AUTOSAR XML (schema 4-2-2)
package /Components
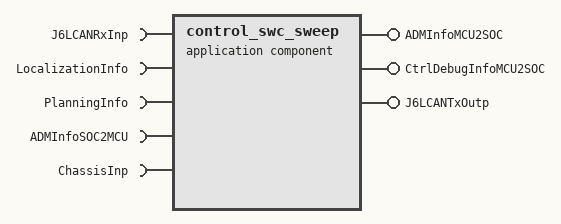
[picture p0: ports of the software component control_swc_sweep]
  application sw component type control_swc_sweep
    5 x require port:
      J6LCANRxInp: nonqueued-receiver-com-spec{data-element=J6LCANRxInp, init-value={short-label=DefaultInitValue_J6L_RxBus, fields=[0, 0, 0, 0, 0, 0, 0, 0, 0, 0, 0, 0, 0, 0, 0, 0, 0, 0, 0, 0, 0, 0, 0, 0, 0, 0, 0, 0, 0, 0, 0, 0, 0, 0, 0, 0, 0, 0, 0, 0, 0, 0, 0, 0, 0, 0, 0, 0, 0, 0, 0, 0, 0, 0, 0, 0, 0, 0, 0, 0, 0, 0, 0, 0, 0, 0, 0, 0, 0, 0, 0, 0, 0, 0, 0, 0, 0, 0, 0, 0, 0, 0, 0, 0, 0, 0, 0, 0, 0, 0, 0, 0, 0, 0, 0, 0, 0, 0, 0, 0, 0, 0, 0, 0, 0, 0, 0, 0, 0, 0, 0, 0, 0, 0, 0, 0, 0, 0, 0, 0, 0, 0, 0, 0, 0, 0, 0, 0, 0, 0, 0, 0, 0, 0, 0, 0, 0, 0, 0, 0, 0, 0, 0, 0, 0, 0, 0, 0, 0, 0, 0, 0, 0, 0, 0, 0, 0, 0, 0, 0, 0, 0, 0, 0, 0, 0, 0, 0, 0, 0, 0, 0, 0, 0, 0, 0, 0, 0, 0, 0, 0, 0, 0, 0, 0, 0, 0, 0, 0, 0, 0, 0, 0, 0, 0, 0, 0, 0, 0, 0, 0, 0, 0, 0, 0, 0, 0, 0, 0, 0, 0, 0, 0, 0, 0, 0, 0, 0, 0, 0, 0, 0, 0, 0, 0, 0, 0, 0, 0, 0, 0, 0, 0, 0, 0, 0, 0, 0, 0, 0, 0, 0, 0, 0, 0, 0, 0, 0, 0, 0, 0, 0, 0, 0, 0, 0, 0, 0, 0, 0, 0, 0, 0, 0, 0, 0, 0, 0, 0, 0, 0, 0, 0, 0, 0, 0, 0, 0, 0, 0, 0, 0, 0, 0, 0, 0, 0, 0, 0, 0, 0, 0, 0, 0, 0, 0, 0, 0, 0, 0, 0, 0, 0, 0, 0, 0, 0, 0, 0, 0, 0, 0, 0, 0, 0, 0, 0, 0, 0, 0, 0, 0, 0, 0, 0, 0, 0, 0, 0, 0, 0, 0, 0, 0, 0, 0, 0, 0, 0, 0, 0, 0, 0, 0, 0, 0, 0, 0, 0, 0, 0, 0, 0, 0, 0, 0, 0, 0, 0, 0, 0]}}, required-interface=J6LCANRxInp
      LocalizationInfo: nonqueued-receiver-com-spec{data-element=LocalizationInfo, init-value={short-label=DefaultInitValue_LocalizationInfo, fields=[0, 0, 0, 0, 0, 0, 0, [0, 0, 0], [0, 0, 0, 0], [0, 0, 0], [0, 0, 0], [0, 0, 0], 0, [0, 0, 0], [0, 0, 0], [0, 0, 0], [0, 0, 0], 0, 0, [0, 0, 0], [0, 0, 0], [0, 0, 0], 0, 0, 0]}}, required-interface=LocalizationInfo
      PlanningInfo: nonqueued-receiver-com-spec{data-element=PlanningInfo, init-value={short-label=DefaultInitValue_PlanningInfo, fields=[0, 0, 0, 0, 0, 0, 0, 0, 0, 0, {short-label=DefaultInitValue_TrajectoryPoint, fields=[100 x 0, 100 x 0, 100 x 0, 100 x 0, 100 x 0, 100 x 0, 100 x 0, 100 x 0, 100 x 0, 100 x 0, 100 x 0, 100 x 0, 100 x 0]}, 0, {short-label=DefaultInitValue_PathPoint, fields=[100 x 0, 100 x 0, 100 x 0, 100 x 0, 100 x 0, 100 x 0, 100 x 0]}, 0, 0, 0, 0, 0, 0, 0, 0, 0, 0, 0, 0, 0, 0, {short-label=DefaultInitValue_VehicleSignal, fields=[0, 0, 0, 0, 0]}, 0, 0]}}, required-interface=PlanningInfo
      ADMInfoSOC2MCU: nonqueued-receiver-com-spec{data-element=ADMInfoSOC2MCU, init-value={short-label=DefaultInitValue_ADMInfoSOC2MCU, fields=[0, 0, 0, 0, 0, 0, 0, 0, 0, 0, 0, 0, 0, 0, 0, 0, 0, 0, 0, 0, 0, 0, 0, 0, 0, 0, 0]}}, required-interface=ADMInfoSOC2MCU
      ChassisInp: nonqueued-receiver-com-spec{data-element=ChassisInp, init-value={short-label=DefaultInitValue_ChassisInfo, fields=[0, 0, 0, 0, 0, 0, 0, 0, 0, 0, 0, 0, 0, 0, 0, 0, 0, 0, 0, 0, 0, 0, 0, 0, 0, 0, 0, 0, 0, 0, 0, 0, 0, 0, 0, 0, 0, 0, 0, 0, 0, 0, 0, 0, 0, 0, 0, 0, 0, 0, 0, 0, 0, 0, 0, 0, 0, 0, 0, 0, 0, 0, 0, 0, 0, 0, 0, 0, 0, 0, 0, 0, 0, 0, 0, 0, 0, 0, 0, 0, 0, 0, 0, 0, 0, 0, 0, 0, 0, 0, 0, 0, 0, 0, 0, 0, 0, 0, 0, 0, 0, 0, 0, 0, 0, 0, 0, 0, 0, 0, 0, 0, 0, 0, 0, 0, 0, 0, 0, 0, 0, 0, 0, 0, 0, 0, 0, 0, 0, 0, 0]}}, required-interface=ChassisInp
    provide port ADMInfoMCU2SOC: nonqueued-sender-com-spec{data-element=ADMInfoMCU2SOC, init-value={short-label=DefaultInitValue_ADMInfoMCU2SOC, fields=[0, 0, 0, 0, 0, 0, 0, 0]}}, provided-interface=ADMInfoMCU2SOC
    provide port CtrlDebugInfoMCU2SOC: nonqueued-sender-com-spec{data-element=CtrlDebugInfoMCU2SOC, init-value={short-label=DefaultInitValue_CtrlInfoMCU2SOC, fields=[0, 0, 0, 0, 0, 0, 0, 0, 0, 0, 0, 0, 0, 0, 0, 0, 0, 0, 0, 0, 0, 0, 0, 0, 0, 0, 0, 0, 0, 0, 0, 0, 0, 0, 0, 0, 0, 0, 0, 0, 0, 0, 0, 0, 0, 0, 0, 0, 0, 0, 0, 0, 0, 0, 0, 0, 0, 0, 0, 0, 0, 0, 0, 0, 0, 0, 0]}}, provided-interface=CtrlDebugInfoMCU2SOC
    provide port J6LCANTxOutp: nonqueued-sender-com-spec{data-element=J6LCANTxOutp, init-value={short-label=DefaultInitValue_J6L_TxBus, fields=[0, 0, 0, 0, 0, 0, 0, 0, 0, 0, 0, 0, 0, 0, 0, 0, 0, 0, 0, 0, 0, 0, 0, 0, 0, 0, 0, 0, 0, 0, 0, 0, 0, 0, 0, 0, 0, 0, 0, 0, 0, 0, 0, 0, 0, 0, 0, 0, 0, 0, 0, 0, 0, 0, 0, 0, 0, 0, 0, 0, 0, 0, 0, 0, 0, 0, 0, 0, 0, 0, 0, 0, 0, 0, 0, 0, 0, 0, 0, 0, 0, 0]}}, provided-interface=J6LCANTxOutp
    behavior control_swc_sweep_IB: handle-termination-and-restart=NO-SUPPORT
      constant-memorys:
        122 x parameter data prototype, all with sw-calibration-access=READ-WRITE:
          k_CRM_LatCrvtPrvTi: category=VALUE, type=Double_const, init-value=constant-reference={short-label=k_CRM_LatCrvtPrvTi, constant=k_CRM_LatCrvtPrvTi}
          k_CRM_LatErrPrvTi: category=VALUE, type=Double_const, init-value=constant-reference={short-label=k_CRM_LatErrPrvTi, constant=k_CRM_LatErrPrvTi}
          k_CRM_LongPrvTi: category=VALUE, type=Double_const, init-value=constant-reference={short-label=k_CRM_LongPrvTi, constant=k_CRM_LongPrvTi}
          k_Lat_SteerAnglErrDisThres: category=VALUE, type=Double_const, init-value=constant-reference={short-label=k_Lat_SteerAnglErrDisThres, constant=k_Lat_SteerAnglErrDisThres}
          k_Lat_SteerAnglOffsetIni: category=VALUE, type=Double_const, init-value=constant-reference={short-label=k_Lat_SteerAnglOffsetIni, constant=k_Lat_SteerAnglOffsetIni}
          k_Lat_SteerAngloffsetAnglThres: category=VALUE, type=Double_const, init-value=constant-reference={short-label=k_Lat_SteerAngloffsetAnglThres, constant=k_Lat_SteerAngloffsetAnglThres}
          k_Lat_SteerAngloffsetHidingErrThres: category=VALUE, type=Double_const, init-value=constant-reference={short-label=k_Lat_SteerAngloffsetHidingErrThres, constant=k_Lat_SteerAngloffsetHidingErrThres}
          k_Lat_SteerAngloffsetHoldTi: category=VALUE, type=Double_const, init-value=constant-reference={short-label=k_Lat_SteerAngloffsetHoldTi, constant=k_Lat_SteerAngloffsetHoldTi}
          k_Lat_SteerAngloffsetLatErrThres: category=VALUE, type=Double_const, init-value=constant-reference={short-label=k_Lat_SteerAngloffsetLatErrThres, constant=k_Lat_SteerAngloffsetLatErrThres}
          k_Lat_SteerAngloffsetWaitTi: category=VALUE, type=Double_const, init-value=constant-reference={short-label=k_Lat_SteerAngloffsetWaitTi, constant=k_Lat_SteerAngloffsetWaitTi}
          k_SigMap_brake_accel_deadzone: category=VALUE, type=Double_const, init-value=constant-reference={short-label=k_SigMap_brake_accel_deadzone, constant=k_SigMap_brake_accel_deadzone}
          k_CRM_DstErrCalibration: category=VALUE, type=Float_const, init-value=constant-reference={short-label=k_CRM_DstErrCalibration, constant=k_CRM_DstErrCalibration}
          k_CRM_LongRefAccCalibration: category=VALUE, type=Float_const, init-value=constant-reference={short-label=k_CRM_LongRefAccCalibration, constant=k_CRM_LongRefAccCalibration}
          k_CRM_LongRefSpdCalibration: category=VALUE, type=Float_const, init-value=constant-reference={short-label=k_CRM_LongRefSpdCalibration, constant=k_CRM_LongRefSpdCalibration}
          k_EPS_StrAnglGain: category=VALUE, type=Float_const, init-value=constant-reference={short-label=k_EPS_StrAnglGain, constant=k_EPS_StrAnglGain}
          k_Lat_DefaultCmd: category=VALUE, type=Float_const, init-value=constant-reference={short-label=k_Lat_DefaultCmd, constant=k_Lat_DefaultCmd}
          k_Lat_DeltaFeedbackStrWhlAngUp: category=ARRAY, type=rt_Array_Float_22_const, init-value=constant-reference={short-label=k_Lat_DeltaFeedbackStrWhlAngUp, constant=k_Lat_DeltaFeedbackStrWhlAngUp}
          k_Lat_DeltaFeedbackStrWhlAngUpUturn: category=VALUE, type=Float_const, init-value=constant-reference={short-label=k_Lat_DeltaFeedbackStrWhlAngUpUturn, constant=k_Lat_DeltaFeedbackStrWhlAngUpUturn}
          k_Lat_DeltaFeedforwardStrWhlAngUp: category=ARRAY, type=rt_Array_Float_22_const, init-value=constant-reference={short-label=k_Lat_DeltaFeedforwardStrWhlAngUp, constant=k_Lat_DeltaFeedforwardStrWhlAngUp}
          k_Lat_DeltaFeedforwardStrWhlAngUpUturn: category=VALUE, type=Float_const, init-value=constant-reference={short-label=k_Lat_DeltaFeedforwardStrWhlAngUpUturn, constant=k_Lat_DeltaFeedforwardStrWhlAngUpUturn}
          k_Lat_DeltaStrWhlAngUp: category=ARRAY, type=rt_Array_Float_22_const, init-value=constant-reference={short-label=k_Lat_DeltaStrWhlAngUp, constant=k_Lat_DeltaStrWhlAngUp}
          k_Lat_DeltaStrWhlAngUpUturn: category=VALUE, type=Float_const, init-value=constant-reference={short-label=k_Lat_DeltaStrWhlAngUpUturn, constant=k_Lat_DeltaStrWhlAngUpUturn}
          k_Lat_DeltaStrWhlAnglforBias: category=VALUE, type=Float_const, init-value=constant-reference={short-label=k_Lat_DeltaStrWhlAnglforBias, constant=k_Lat_DeltaStrWhlAnglforBias}
          k_Lat_DuWeight: category=VALUE, type=Float_const, init-value=constant-reference={short-label=k_Lat_DuWeight, constant=k_Lat_DuWeight}
          k_Lat_FbResetVxThd: category=VALUE, type=Float_const, init-value=constant-reference={short-label=k_Lat_FbResetVxThd, constant=k_Lat_FbResetVxThd}
          k_Lat_LQR_HeadingError_Weights: category=ARRAY, type=rt_Array_Float_22_const, init-value=constant-reference={short-label=k_Lat_LQR_HeadingError_Weights, constant=k_Lat_LQR_HeadingError_Weights}
          k_Lat_LQR_K_Matrics: category=ARRAY, type=rt_Array_Float_292_const, init-value=constant-reference={short-label=k_Lat_LQR_K_Matrics, constant=k_Lat_LQR_K_Matrics}
          k_Lat_LQR_LatError_Weights: category=ARRAY, type=rt_Array_Float_22_const, init-value=constant-reference={short-label=k_Lat_LQR_LatError_Weights, constant=k_Lat_LQR_LatError_Weights}
          k_Lat_ManualCmd: category=VALUE, type=Float_const, init-value=constant-reference={short-label=k_Lat_ManualCmd, constant=k_Lat_ManualCmd}
          k_Lat_MaxLatAcc: category=VALUE, type=Float_const, init-value=constant-reference={short-label=k_Lat_MaxLatAcc, constant=k_Lat_MaxLatAcc}
          k_Lat_MaxStrWhlAng: category=ARRAY, type=rt_Array_Float_22_const, init-value=constant-reference={short-label=k_Lat_MaxStrWhlAng, constant=k_Lat_MaxStrWhlAng}
          k_Lat_PPMinDist: category=VALUE, type=Float_const, init-value=constant-reference={short-label=k_Lat_PPMinDist, constant=k_Lat_PPMinDist}
          k_Lat_PP_PrvTi: category=VALUE, type=Float_const, init-value=constant-reference={short-label=k_Lat_PP_PrvTi, constant=k_Lat_PP_PrvTi}
          k_Lat_SteerAngloffset: category=VALUE, type=Float_const, init-value=constant-reference={short-label=k_Lat_SteerAngloffset, constant=k_Lat_SteerAngloffset}
          k_Lat_UWeight: category=VALUE, type=Float_const, init-value=constant-reference={short-label=k_Lat_UWeight, constant=k_Lat_UWeight}
          k_Lat_feedforwardhidingindex: category=ARRAY, type=rt_Array_Float_25_const, init-value=constant-reference={short-label=k_Lat_feedforwardhidingindex, constant=k_Lat_feedforwardhidingindex}
          k_Lat_feedforwardindex: category=ARRAY, type=rt_Array_Float_25_const, init-value=constant-reference={short-label=k_Lat_feedforwardindex, constant=k_Lat_feedforwardindex}
          k_Lat_lqrtolerance: category=VALUE, type=Float_const, init-value=constant-reference={short-label=k_Lat_lqrtolerance, constant=k_Lat_lqrtolerance}
          k_Lat_maxiteration: category=VALUE, type=Float_const, init-value=constant-reference={short-label=k_Lat_maxiteration, constant=k_Lat_maxiteration}
          k_Lat_steerratioindex: category=VALUE, type=Float_const, init-value=constant-reference={short-label=k_Lat_steerratioindex, constant=k_Lat_steerratioindex}
          k_LongCtrl_DistCtrl_I_LowLmt: category=VALUE, type=Float_const, init-value=constant-reference={short-label=k_LongCtrl_DistCtrl_I_LowLmt, constant=k_LongCtrl_DistCtrl_I_LowLmt}
          k_LongCtrl_DistCtrl_I_UppLmt: category=VALUE, type=Float_const, init-value=constant-reference={short-label=k_LongCtrl_DistCtrl_I_UppLmt, constant=k_LongCtrl_DistCtrl_I_UppLmt}
          k_LongCtrl_DistCtrl_LowLmt: category=VALUE, type=Float_const, init-value=constant-reference={short-label=k_LongCtrl_DistCtrl_LowLmt, constant=k_LongCtrl_DistCtrl_LowLmt}
          k_LongCtrl_DistCtrl_P_LowLmt: category=VALUE, type=Float_const, init-value=constant-reference={short-label=k_LongCtrl_DistCtrl_P_LowLmt, constant=k_LongCtrl_DistCtrl_P_LowLmt}
          k_LongCtrl_DistCtrl_P_UppLmt: category=VALUE, type=Float_const, init-value=constant-reference={short-label=k_LongCtrl_DistCtrl_P_UppLmt, constant=k_LongCtrl_DistCtrl_P_UppLmt}
          k_LongCtrl_DistCtrl_UppLmt: category=VALUE, type=Float_const, init-value=constant-reference={short-label=k_LongCtrl_DistCtrl_UppLmt, constant=k_LongCtrl_DistCtrl_UppLmt}
          k_LongCtrl_DistErrLImit_sweep: category=VALUE, type=Float_const, init-value=constant-reference={short-label=k_LongCtrl_DistErrLImit_sweep, constant=k_LongCtrl_DistErrLImit_sweep}
          k_LongCtrl_Dist_P_term_filter_gain: category=VALUE, type=Float_const, init-value=constant-reference={short-label=k_LongCtrl_Dist_P_term_filter_gain, constant=k_LongCtrl_Dist_P_term_filter_gain}
          k_LongCtrl_Freeze_DeltaDistErr_UppLmt_sweep: category=VALUE, type=Float_const, init-value=constant-reference={short-label=k_LongCtrl_Freeze_DeltaDistErr_UppLmt_sweep, constant=k_LongCtrl_Freeze_DeltaDistErr_UppLmt_sweep}
          k_LongCtrl_Freeze_DistErr_UppLmt_sweep: category=VALUE, type=Float_const, init-value=constant-reference={short-label=k_LongCtrl_Freeze_DistErr_UppLmt_sweep, constant=k_LongCtrl_Freeze_DistErr_UppLmt_sweep}
          k_LongCtrl_I_term_for_Disterr_y_sweep: category=ARRAY, type=rt_Array_Float_7_const, init-value=constant-reference={short-label=k_LongCtrl_I_term_for_Disterr_y_sweep, constant=k_LongCtrl_I_term_for_Disterr_y_sweep}
          k_LongCtrl_I_term_for_Disterr_y_sweep_reverse: category=ARRAY, type=rt_Array_Float_7_const, init-value=constant-reference={short-label=k_LongCtrl_I_term_for_Disterr_y_sweep_reverse, constant=k_LongCtrl_I_term_for_Disterr_y_sweep_reverse}
          k_LongCtrl_LongAccelFiltParam: category=VALUE, type=Float_const, init-value=constant-reference={short-label=k_LongCtrl_LongAccelFiltParam, constant=k_LongCtrl_LongAccelFiltParam}
          k_LongCtrl_P_Uturn: category=VALUE, type=Float_const, init-value=constant-reference={short-label=k_LongCtrl_P_Uturn, constant=k_LongCtrl_P_Uturn}
          k_LongCtrl_P_term_for_Disterr_y_sweep: category=ARRAY, type=rt_Array_Float_7_const, init-value=constant-reference={short-label=k_LongCtrl_P_term_for_Disterr_y_sweep, constant=k_LongCtrl_P_term_for_Disterr_y_sweep}
          k_LongCtrl_P_term_for_Disterr_y_sweep_reverse: category=ARRAY, type=rt_Array_Float_7_const, init-value=constant-reference={short-label=k_LongCtrl_P_term_for_Disterr_y_sweep_reverse, constant=k_LongCtrl_P_term_for_Disterr_y_sweep_reverse}
          k_LongCtrl_PitchAnglFiltParam: category=VALUE, type=Float_const, init-value=constant-reference={short-label=k_LongCtrl_PitchAnglFiltParam, constant=k_LongCtrl_PitchAnglFiltParam}
          k_LongCtrl_RoadGrdAccel: category=VALUE, type=Float_const, init-value=constant-reference={short-label=k_LongCtrl_RoadGrdAccel, constant=k_LongCtrl_RoadGrdAccel}
          k_LongCtrl_accel_limit_max_for_sweep_y: category=ARRAY, type=rt_Array_Float_5_const, init-value=constant-reference={short-label=k_LongCtrl_accel_limit_max_for_sweep_y, constant=k_LongCtrl_accel_limit_max_for_sweep_y}
          k_LongCtrl_accel_limit_min_for_sweep_y: category=ARRAY, type=rt_Array_Float_2_const, init-value=constant-reference={short-label=k_LongCtrl_accel_limit_min_for_sweep_y, constant=k_LongCtrl_accel_limit_min_for_sweep_y}
          k_LongCtrl_engine_Freeze_DeltaSpdErr_UppLmt_sweep: category=VALUE, type=Float_const, init-value=constant-reference={short-label=k_LongCtrl_engine_Freeze_DeltaSpdErr_UppLmt_sweep, constant=k_LongCtrl_engine_Freeze_DeltaSpdErr_UppLmt_sweep}
          k_LongCtrl_engine_Freeze_SpdErr_UppLmt: category=VALUE, type=Float_const, init-value=constant-reference={short-label=k_LongCtrl_engine_Freeze_SpdErr_UppLmt, constant=k_LongCtrl_engine_Freeze_SpdErr_UppLmt}
          k_LongCtrl_engine_I_LowLmt: category=VALUE, type=Float_const, init-value=constant-reference={short-label=k_LongCtrl_engine_I_LowLmt, constant=k_LongCtrl_engine_I_LowLmt}
          k_LongCtrl_engine_I_UppLmt: category=VALUE, type=Float_const, init-value=constant-reference={short-label=k_LongCtrl_engine_I_UppLmt, constant=k_LongCtrl_engine_I_UppLmt}
          k_LongCtrl_engine_I_term_for_spderr_y: category=ARRAY, type=rt_Array_Float_9_const, init-value=constant-reference={short-label=k_LongCtrl_engine_I_term_for_spderr_y, constant=k_LongCtrl_engine_I_term_for_spderr_y}
          k_LongCtrl_engine_I_term_for_spderr_y_sweep_HighSpeed: category=ARRAY, type=rt_Array_Float_9_const, init-value=constant-reference={short-label=k_LongCtrl_engine_I_term_for_spderr_y_sweep_HighSpeed, constant=k_LongCtrl_engine_I_term_for_spderr_y_sweep_HighSpeed}
          k_LongCtrl_engine_I_term_for_spderr_y_sweep_LowSpeed: category=ARRAY, type=rt_Array_Float_9_const, init-value=constant-reference={short-label=k_LongCtrl_engine_I_term_for_spderr_y_sweep_LowSpeed, constant=k_LongCtrl_engine_I_term_for_spderr_y_sweep_LowSpeed}
          k_LongCtrl_engine_I_term_for_spderr_y_sweep_Reverse: category=ARRAY, type=rt_Array_Float_9_const, init-value=constant-reference={short-label=k_LongCtrl_engine_I_term_for_spderr_y_sweep_Reverse, constant=k_LongCtrl_engine_I_term_for_spderr_y_sweep_Reverse}
          k_LongCtrl_engine_LowLmt: category=VALUE, type=Float_const, init-value=constant-reference={short-label=k_LongCtrl_engine_LowLmt, constant=k_LongCtrl_engine_LowLmt}
          k_LongCtrl_engine_P_LowLmt: category=VALUE, type=Float_const, init-value=constant-reference={short-label=k_LongCtrl_engine_P_LowLmt, constant=k_LongCtrl_engine_P_LowLmt}
          k_LongCtrl_engine_P_UppLmt: category=VALUE, type=Float_const, init-value=constant-reference={short-label=k_LongCtrl_engine_P_UppLmt, constant=k_LongCtrl_engine_P_UppLmt}
          k_LongCtrl_engine_P_term_filter_gain: category=VALUE, type=Float_const, init-value=constant-reference={short-label=k_LongCtrl_engine_P_term_filter_gain, constant=k_LongCtrl_engine_P_term_filter_gain}
          k_LongCtrl_engine_P_term_for_spderr_y: category=ARRAY, type=rt_Array_Float_9_const, init-value=constant-reference={short-label=k_LongCtrl_engine_P_term_for_spderr_y, constant=k_LongCtrl_engine_P_term_for_spderr_y}
          k_LongCtrl_engine_P_term_for_spderr_y_sweep_HighSpeed: category=ARRAY, type=rt_Array_Float_9_const, init-value=constant-reference={short-label=k_LongCtrl_engine_P_term_for_spderr_y_sweep_HighSpeed, constant=k_LongCtrl_engine_P_term_for_spderr_y_sweep_HighSpeed}
          k_LongCtrl_engine_P_term_for_spderr_y_sweep_Reverse: category=ARRAY, type=rt_Array_Float_9_const, init-value=constant-reference={short-label=k_LongCtrl_engine_P_term_for_spderr_y_sweep_Reverse, constant=k_LongCtrl_engine_P_term_for_spderr_y_sweep_Reverse}
          k_LongCtrl_engine_P_term_for_spderr_y_sweep_lowSpeed: category=ARRAY, type=rt_Array_Float_9_const, init-value=constant-reference={short-label=k_LongCtrl_engine_P_term_for_spderr_y_sweep_lowSpeed, constant=k_LongCtrl_engine_P_term_for_spderr_y_sweep_lowSpeed}
          k_LongCtrl_engine_UppLmt: category=VALUE, type=Float_const, init-value=constant-reference={short-label=k_LongCtrl_engine_UppLmt, constant=k_LongCtrl_engine_UppLmt}
          k_LongCtrl_engine_accel_filter_gain: category=VALUE, type=Float_const, init-value=constant-reference={short-label=k_LongCtrl_engine_accel_filter_gain, constant=k_LongCtrl_engine_accel_filter_gain}
          k_LongCtrl_jerk_limit_max_for_sweep_y: category=ARRAY, type=rt_Array_Float_5_const, init-value=constant-reference={short-label=k_LongCtrl_jerk_limit_max_for_sweep_y, constant=k_LongCtrl_jerk_limit_max_for_sweep_y}
          k_LongCtrl_jerk_limit_min_for_sweep_y: category=ARRAY, type=rt_Array_Float_5_const, init-value=constant-reference={short-label=k_LongCtrl_jerk_limit_min_for_sweep_y, constant=k_LongCtrl_jerk_limit_min_for_sweep_y}
          k_LongCtrl_sweep_jerk_limit_max_for_brake_y: category=ARRAY, type=rt_Array_Float_5_const, init-value=constant-reference={short-label=k_LongCtrl_sweep_jerk_limit_max_for_brake_y, constant=k_LongCtrl_sweep_jerk_limit_max_for_brake_y}
          k_LongCtrl_sweep_jerk_limit_max_for_engine_y: category=ARRAY, type=rt_Array_Float_5_const, init-value=constant-reference={short-label=k_LongCtrl_sweep_jerk_limit_max_for_engine_y, constant=k_LongCtrl_sweep_jerk_limit_max_for_engine_y}
          k_LongCtrl_sweep_jerk_limit_min_for_brake_y: category=ARRAY, type=rt_Array_Float_5_const, init-value=constant-reference={short-label=k_LongCtrl_sweep_jerk_limit_min_for_brake_y, constant=k_LongCtrl_sweep_jerk_limit_min_for_brake_y}
          k_LongCtrl_sweep_jerk_limit_min_for_engine_y: category=ARRAY, type=rt_Array_Float_5_const, init-value=constant-reference={short-label=k_LongCtrl_sweep_jerk_limit_min_for_engine_y, constant=k_LongCtrl_sweep_jerk_limit_min_for_engine_y}
          k_SigMap_DragAcc: category=VALUE, type=Float_const, init-value=constant-reference={short-label=k_SigMap_DragAcc, constant=k_SigMap_DragAcc}
          k_SigMap_MotorRefTrq: category=VALUE, type=Float_const, init-value=constant-reference={short-label=k_SigMap_MotorRefTrq, constant=k_SigMap_MotorRefTrq}
          k_SigMap_SpdReducerRatio: category=VALUE, type=Float_const, init-value=constant-reference={short-label=k_SigMap_SpdReducerRatio, constant=k_SigMap_SpdReducerRatio}
          k_SigMap_WhlRadius: category=VALUE, type=Float_const, init-value=constant-reference={short-label=k_SigMap_WhlRadius, constant=k_SigMap_WhlRadius}
          k_SigMap_torque_pid_conf_ki: category=ARRAY, type=rt_Array_Float_9_const, init-value=constant-reference={short-label=k_SigMap_torque_pid_conf_ki, constant=k_SigMap_torque_pid_conf_ki}
          k_SigMap_torque_pid_conf_kp: category=ARRAY, type=rt_Array_Float_9_const, init-value=constant-reference={short-label=k_SigMap_torque_pid_conf_kp, constant=k_SigMap_torque_pid_conf_kp}
          k_VSE_cf: category=VALUE, type=Float_const, init-value=constant-reference={short-label=k_VSE_cf, constant=k_VSE_cf}
          k_VSE_cr: category=VALUE, type=Float_const, init-value=constant-reference={short-label=k_VSE_cr, constant=k_VSE_cr}
          k_VSE_mass_rearleft: category=VALUE, type=Float_const, init-value=constant-reference={short-label=k_VSE_mass_rearleft, constant=k_VSE_mass_rearleft}
          k_VSE_mass_rearright: category=VALUE, type=Float_const, init-value=constant-reference={short-label=k_VSE_mass_rearright, constant=k_VSE_mass_rearright}
          k_VSE_massfrontleft: category=VALUE, type=Float_const, init-value=constant-reference={short-label=k_VSE_massfrontleft, constant=k_VSE_massfrontleft}
          k_VSE_massfrontright: category=VALUE, type=Float_const, init-value=constant-reference={short-label=k_VSE_massfrontright, constant=k_VSE_massfrontright}
          k_VSE_totalmass: category=VALUE, type=Float_const, init-value=constant-reference={short-label=k_VSE_totalmass, constant=k_VSE_totalmass}
          k_VSE_wheelbase: category=VALUE, type=Float_const, init-value=constant-reference={short-label=k_VSE_wheelbase, constant=k_VSE_wheelbase}
          k_Veh_FrontWhl2StrWhl_Ratio: category=VALUE, type=Float_const, init-value=constant-reference={short-label=k_Veh_FrontWhl2StrWhl_Ratio, constant=k_Veh_FrontWhl2StrWhl_Ratio}
          k_lat_CrvtOffset: category=ARRAY, type=rt_Array_Float_8_const, init-value=constant-reference={short-label=k_lat_CrvtOffset, constant=k_lat_CrvtOffset}
          k_ADM_LocTiThres: category=VALUE, type=UInt16_const, init-value=constant-reference={short-label=k_ADM_LocTiThres, constant=k_ADM_LocTiThres}
          k_ADM_PlanTiThres: category=VALUE, type=UInt16_const, init-value=constant-reference={short-label=k_ADM_PlanTiThres, constant=k_ADM_PlanTiThres}
          k_CRM_CrvtUsingNearestPoint: category=VALUE, type=Boolean_const, init-value=constant-reference={short-label=k_CRM_CrvtUsingNearestPoint, constant=k_CRM_CrvtUsingNearestPoint}
          k_CRM_UsingPositionNearest: category=VALUE, type=Boolean_const, init-value=constant-reference={short-label=k_CRM_UsingPositionNearest, constant=k_CRM_UsingPositionNearest}
          k_CRM_UsingTrajPointCalc: category=VALUE, type=Boolean_const, init-value=constant-reference={short-label=k_CRM_UsingTrajPointCalc, constant=k_CRM_UsingTrajPointCalc}
          k_EM_LocPosFarFromTrajErrSwt: category=VALUE, type=Boolean_const, init-value=constant-reference={short-label=k_EM_LocPosFarFromTrajErrSwt, constant=k_EM_LocPosFarFromTrajErrSwt}
          k_Lat_LQR_Online: category=VALUE, type=Boolean_const, init-value=constant-reference={short-label=k_Lat_LQR_Online, constant=k_Lat_LQR_Online}
          k_Lat_LqrDuSwt: category=VALUE, type=Boolean_const, init-value=constant-reference={short-label=k_Lat_LqrDuSwt, constant=k_Lat_LqrDuSwt}
          k_Lat_ManualOption: category=VALUE, type=Boolean_const, init-value=constant-reference={short-label=k_Lat_ManualOption, constant=k_Lat_ManualOption}
          k_Lat_PPForceSwt: category=VALUE, type=Boolean_const, init-value=constant-reference={short-label=k_Lat_PPForceSwt, constant=k_Lat_PPForceSwt}
          k_Lat_PPSwt: category=VALUE, type=Boolean_const, init-value=constant-reference={short-label=k_Lat_PPSwt, constant=k_Lat_PPSwt}
          k_Lat_SteerAngloffsetManual: category=VALUE, type=Boolean_const, init-value=constant-reference={short-label=k_Lat_SteerAngloffsetManual, constant=k_Lat_SteerAngloffsetManual}
          k_Lat_isuturn: category=VALUE, type=Boolean_const, init-value=constant-reference={short-label=k_Lat_isuturn, constant=k_Lat_isuturn}
          k_LongCtrl_GrdAccelCompEnable: category=VALUE, type=Boolean_const, init-value=constant-reference={short-label=k_LongCtrl_GrdAccelCompEnable, constant=k_LongCtrl_GrdAccelCompEnable}
          k_ADM_ManualActvSwt: category=VALUE, type=UInt8_const, init-value=constant-reference={short-label=k_ADM_ManualActvSwt, constant=k_ADM_ManualActvSwt}
          k_ADM_SimActvSwt: category=VALUE, type=UInt8_const, init-value=constant-reference={short-label=k_ADM_SimActvSwt, constant=k_ADM_SimActvSwt}
          k_CRM_Calibration_Enable: category=VALUE, type=UInt8_const, init-value=constant-reference={short-label=k_CRM_Calibration_Enable, constant=k_CRM_Calibration_Enable}
          k_LongCtrl_P_UturnSwt: category=VALUE, type=UInt8_const, init-value=constant-reference={short-label=k_LongCtrl_P_UturnSwt, constant=k_LongCtrl_P_UturnSwt}
          k_SigMap_LatAccCmpSwt: category=VALUE, type=UInt8_const, init-value=constant-reference={short-label=k_SigMap_LatAccCmpSwt, constant=k_SigMap_LatAccCmpSwt}
          k_SigMap_ManualTrqSwt: category=VALUE, type=UInt8_const, init-value=constant-reference={short-label=k_SigMap_ManualTrqSwt, constant=k_SigMap_ManualTrqSwt}
          k_SigMap_trq_PI_swt: category=VALUE, type=UInt8_const, init-value=constant-reference={short-label=k_SigMap_trq_PI_swt, constant=k_SigMap_trq_PI_swt}
          k_VSE_SpdSource: category=VALUE, type=UInt8_const, init-value=constant-reference={short-label=k_VSE_SpdSource, constant=k_VSE_SpdSource}
      7 x timing event, all with period=0.02:
        Event_EM_20ms: start-on-event=EM_20ms
        Event_ADM_20ms: start-on-event=ADM_20ms
        Event_VSE_20ms: start-on-event=VSE_20ms
        Event_CRM_20ms: start-on-event=CRM_20ms
        Event_LongCtrl_20ms: start-on-event=LongCtrl_20ms
        Event_LatCtrl_20ms: start-on-event=LatCtrl_20ms
        Event_Tx_20ms: start-on-event=Tx_20ms
      implicit-inter-runnable-variables:
        6 x data, all with category=STRUCTURE, sw-calibration-access=READ-ONLY:
          EMOutp: type=BusEM, init-value={short-label=DefaultInitValue_BusEM, fields=[0, 0]}
          ADMOutp: type=BusADM, init-value={short-label=DefaultInitValue_BusADM, fields=[0, 0]}
          VSEOutp: type=BusVSE, init-value={short-label=DefaultInitValue_BusVSE, fields=[0, 0, 0, 0, 0, 0, 0, 0, 0, 0, 0, 0, 0, 0, 0, 0, 0, 0, 0, 0]}
          CRMOutp: type=BusCRM, init-value={short-label=DefaultInitValue_BusCRM, fields=[0, 0, 0, 0, 0, 0, 0, 0]}
          LongCtrlOutp: type=BusLongCtrl, init-value={short-label=DefaultInitValue_BusLongCtrl, fields=[0, 0, 0, 0, 0, 0, 0, 0, 0, 0, 0, 0, 0, 0, 0, 0, 0, 0, 0, 0, 0]}
          LatCtrlOutp: type=BusLatCtrl, init-value={short-label=DefaultInitValue_BusLatCtrl, fields=[0, 0]}
      8 x runnable:
        control_swc_sweep_Init
        EM_20ms
          data-read-access:
            4 x access:
              IN_ADMInfoSOC2MCU_ADMInfoSOC2MCU: accessed-variable=ADMInfoSOC2MCU.ADMInfoSOC2MCU
              IN_J6LCANRxInp_J6LCANRxInp: accessed-variable=J6LCANRxInp.J6LCANRxInp
              IN_LocalizationInfo_LocalizationInfo: accessed-variable=LocalizationInfo.LocalizationInfo
              IN_PlanningInfo_PlanningInfo: accessed-variable=PlanningInfo.PlanningInfo
          written-local-variables:
            access WV_EMOutp: accessed-variable=EMOutp
        ADM_20ms
          data-read-access:
            4 x access:
              IN_ADMInfoSOC2MCU_ADMInfoSOC2MCU: accessed-variable=ADMInfoSOC2MCU.ADMInfoSOC2MCU
              IN_ChassisInp_ChassisInp: accessed-variable=ChassisInp.ChassisInp
              IN_J6LCANRxInp_J6LCANRxInp: accessed-variable=J6LCANRxInp.J6LCANRxInp
              IN_PlanningInfo_PlanningInfo: accessed-variable=PlanningInfo.PlanningInfo
          read-local-variables:
            access RV_EMOutp: accessed-variable=EMOutp
          written-local-variables:
            access WV_ADMOutp: accessed-variable=ADMOutp
        VSE_20ms
          data-read-access:
            access IN_ChassisInp_ChassisInp: accessed-variable=ChassisInp.ChassisInp
            access IN_LocalizationInfo_LocalizationInfo: accessed-variable=LocalizationInfo.LocalizationInfo
          written-local-variables:
            access WV_VSEOutp: accessed-variable=VSEOutp
        CRM_20ms
          data-read-access:
            access IN_PlanningInfo_PlanningInfo: accessed-variable=PlanningInfo.PlanningInfo
          read-local-variables:
            access RV_VSEOutp: accessed-variable=VSEOutp
          written-local-variables:
            access WV_CRMOutp: accessed-variable=CRMOutp
        LongCtrl_20ms
          data-read-access:
            access IN_ChassisInp_ChassisInp: accessed-variable=ChassisInp.ChassisInp
            access IN_PlanningInfo_PlanningInfo: accessed-variable=PlanningInfo.PlanningInfo
          read-local-variables:
            access RV_ADMOutp: accessed-variable=ADMOutp
            access RV_CRMOutp: accessed-variable=CRMOutp
            access RV_VSEOutp: accessed-variable=VSEOutp
          written-local-variables:
            access WV_LongCtrlOutp: accessed-variable=LongCtrlOutp
        LatCtrl_20ms
          data-read-access:
            access IN_PlanningInfo_PlanningInfo: accessed-variable=PlanningInfo.PlanningInfo
          read-local-variables:
            access RV_ADMOutp: accessed-variable=ADMOutp
            access RV_CRMOutp: accessed-variable=CRMOutp
            access RV_VSEOutp: accessed-variable=VSEOutp
          written-local-variables:
            access WV_LatCtrlOutp: accessed-variable=LatCtrlOutp
        Tx_20ms
          data-read-access:
            access IN_PlanningInfo_PlanningInfo: accessed-variable=PlanningInfo.PlanningInfo
          data-write-access:
            access OUT_J6LCANTxOutp_J6LCANTxOutp: accessed-variable=J6LCANTxOutp.J6LCANTxOutp
            access OUT_ADMInfoMCU2SOC_ADMInfoMCU2SOC: accessed-variable=ADMInfoMCU2SOC.ADMInfoMCU2SOC
            access OUT_CtrlDebugInfoMCU2SOC_CtrlDebugInfoMCU2SOC: accessed-variable=CtrlDebugInfoMCU2SOC.CtrlDebugInfoMCU2SOC
          read-local-variables:
            access RV_ADMOutp: accessed-variable=ADMOutp
            access RV_LatCtrlOutp: accessed-variable=LatCtrlOutp
            access RV_LongCtrlOutp: accessed-variable=LongCtrlOutp
